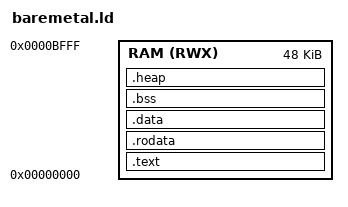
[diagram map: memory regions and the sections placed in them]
/*
 * Linker script for 'bare metal' PicoRV32 firmware running from on-chip BSRAM.
 *
 * The firmware lives entirely in a single 64 KB BSRAM region starting at address
 * 0 (the PicoRV32 reset vector). Code, rodata, data, bss and stack are packed
 * contiguously from 0 so the image is dense (no multi-MB gap) and fits the BSRAM
 * boot RAM generated by bin2bram.py. STACK grows down from the top of the 64 KB.
 *
 * IMPORTANT: keep total (text+rodata+data+bss+stack) <= 64 KB. The build will
 * fail in bin2bram.py if the image exceeds BRAM_DEPTH; watch the stack (set in
 * start.S STACK_TOP) against actual usage.
 */
MEMORY
{
    RAM (RWX): ORIGIN = 0x00000, LENGTH = 48K
}
ENTRY(_start)
SECTIONS
{
    .text :
    {
        start.o (.text)
        *(.text)
        *(.text*)
        _end = .;
    } >RAM

    .rodata :
    {
        . = ALIGN(4);
        *(.rodata)
        *(.rodata*)
        *(.srodata)
        *(.srodata*)
        . = ALIGN(4);
    } >RAM

    /* global and static variables with initial values */
    .data :
    {
        . = ALIGN(4);
        _sdata = .;
        *(.data)
        *(.data*)
        *(.sdata)
        *(.sdata*)
        . = ALIGN(4);
        _edata = .;
    } >RAM

    /* zero-initialised globals/statics (cleared by start.S) */
    .bss :
    {
        . = ALIGN(4);
        _sbss = .;
        *(.bss)
        *(.bss*)
        *(.sbss)
        *(.sbss*)
        *(COMMON)
        . = ALIGN(4);
        _ebss = .;
    } >RAM

    .heap :
    {
        . = ALIGN(4);
        _heap_start = .;
    } >RAM
}

/* Guard: text+data+bss must leave at least 4 KB of stack below STACK_TOP (0xC000).
 * Without this, a growing image silently eats the stack and the firmware corrupts
 * its own globals at runtime (symptom: "cannot init sd" + hang at boot). */
ASSERT(_ebss <= 0xB000, "firmware too large: less than 4 KB left for the stack")
